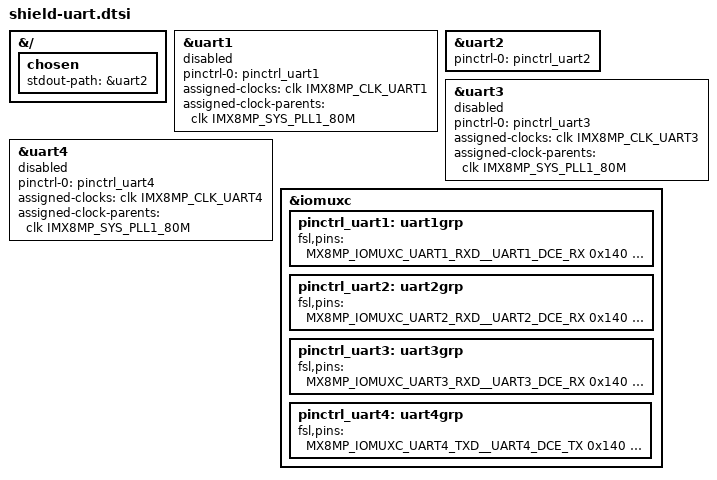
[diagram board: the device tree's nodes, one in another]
// SPDX-License-Identifier: (GPL-2.0+ OR MIT)
/*
 * Copyright 2025 CriticalShift
 */

&{/} {
	chosen {
		stdout-path = &uart2;
	};
};

&uart1 {
	pinctrl-names = "default";
	pinctrl-0 = <&pinctrl_uart1>;
	assigned-clocks = <&clk IMX8MP_CLK_UART1>;
	assigned-clock-parents = <&clk IMX8MP_SYS_PLL1_80M>;
	status = "disabled";
};

/* A53 UART debug */
&uart2 {
	pinctrl-names = "default";
	pinctrl-0 = <&pinctrl_uart2>;
	status = "okay";
};

&uart3 {
	pinctrl-names = "default";
	pinctrl-0 = <&pinctrl_uart3>;
	assigned-clocks = <&clk IMX8MP_CLK_UART3>;
	assigned-clock-parents = <&clk IMX8MP_SYS_PLL1_80M>;
	status = "disabled";
};

/* M7 UART debug */
&uart4 {
	pinctrl-names = "default";
	pinctrl-0 = <&pinctrl_uart4>;
	assigned-clocks = <&clk IMX8MP_CLK_UART4>;
	assigned-clock-parents = <&clk IMX8MP_SYS_PLL1_80M>;
	status = "disabled";
};

&iomuxc {
    pinctrl_uart1: uart1grp {
		fsl,pins = <
			MX8MP_IOMUXC_UART1_RXD__UART1_DCE_RX				0x140
			MX8MP_IOMUXC_UART1_TXD__UART1_DCE_TX				0x140
		>;
	};

	pinctrl_uart2: uart2grp {
		fsl,pins = <
			MX8MP_IOMUXC_UART2_RXD__UART2_DCE_RX				0x140
			MX8MP_IOMUXC_UART2_TXD__UART2_DCE_TX				0x140
		>;
	};

	pinctrl_uart3: uart3grp {
		fsl,pins = <
			MX8MP_IOMUXC_UART3_RXD__UART3_DCE_RX				0x140
			MX8MP_IOMUXC_UART3_TXD__UART3_DCE_TX				0x140
		>;
	};

	pinctrl_uart4: uart4grp {
		fsl,pins = <
			MX8MP_IOMUXC_UART4_TXD__UART4_DCE_TX				0x140
			MX8MP_IOMUXC_UART4_RXD__UART4_DCE_RX				0x140
		>;
	};
};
